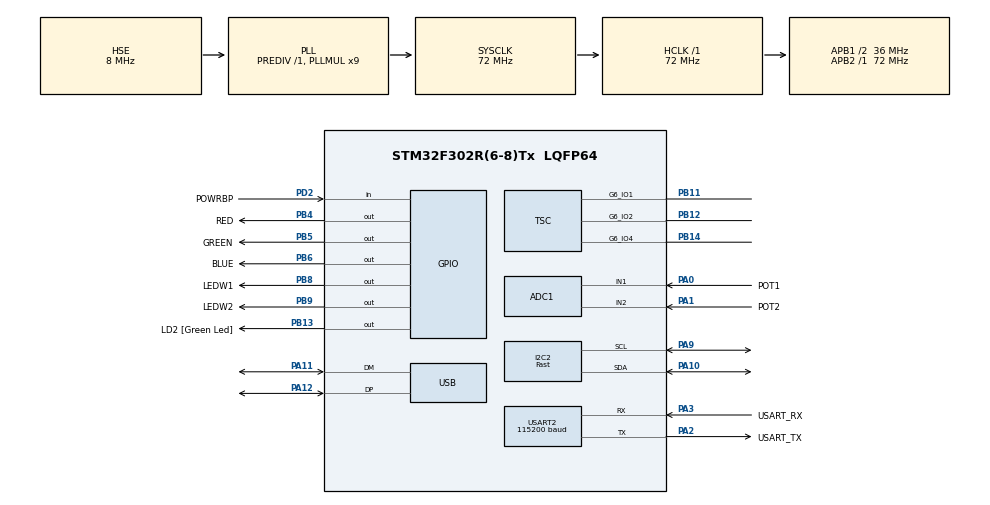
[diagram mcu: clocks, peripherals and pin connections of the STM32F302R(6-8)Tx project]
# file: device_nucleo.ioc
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ADC1.Channel-0\#ChannelRegularConversion=ADC_CHANNEL_1
ADC1.NbrOfConversionFlag=1
ADC1.Offset-0\#ChannelRegularConversion=0
ADC1.OffsetNumber-0\#ChannelRegularConversion=ADC_OFFSET_NONE
ADC1.Rank-0\#ChannelRegularConversion=1
ADC1.SamplingTime-0\#ChannelRegularConversion=ADC_SAMPLETIME_1CYCLE_5
ADC1.SubFamily=STM32F302x8
ADC1.master=1
Dma.ADC1.4.Direction=DMA_PERIPH_TO_MEMORY
Dma.ADC1.4.Instance=DMA1_Channel1
Dma.ADC1.4.MemDataAlignment=DMA_MDATAALIGN_HALFWORD
Dma.ADC1.4.MemInc=DMA_MINC_ENABLE
Dma.ADC1.4.Mode=DMA_NORMAL
Dma.ADC1.4.PeriphDataAlignment=DMA_PDATAALIGN_HALFWORD
Dma.ADC1.4.PeriphInc=DMA_PINC_DISABLE
Dma.ADC1.4.Priority=DMA_PRIORITY_LOW
Dma.I2C2_RX.2.Direction=DMA_PERIPH_TO_MEMORY
Dma.I2C2_RX.2.Instance=DMA1_Channel5
Dma.I2C2_RX.2.MemDataAlignment=DMA_MDATAALIGN_BYTE
Dma.I2C2_RX.2.MemInc=DMA_MINC_ENABLE
Dma.I2C2_RX.2.Mode=DMA_NORMAL
Dma.I2C2_RX.2.PeriphDataAlignment=DMA_PDATAALIGN_BYTE
Dma.I2C2_RX.2.PeriphInc=DMA_PINC_DISABLE
Dma.I2C2_RX.2.Priority=DMA_PRIORITY_LOW
Dma.I2C2_TX.3.Direction=DMA_MEMORY_TO_PERIPH
Dma.I2C2_TX.3.Instance=DMA1_Channel4
Dma.I2C2_TX.3.MemDataAlignment=DMA_MDATAALIGN_BYTE
Dma.I2C2_TX.3.MemInc=DMA_MINC_ENABLE
Dma.I2C2_TX.3.Mode=DMA_NORMAL
Dma.I2C2_TX.3.PeriphDataAlignment=DMA_PDATAALIGN_BYTE
Dma.I2C2_TX.3.PeriphInc=DMA_PINC_DISABLE
Dma.I2C2_TX.3.Priority=DMA_PRIORITY_LOW
Dma.Request0=USART2_RX
Dma.Request1=USART2_TX
Dma.Request2=I2C2_RX
Dma.Request3=I2C2_TX
Dma.Request4=ADC1
Dma.USART2_RX.0.Direction=DMA_PERIPH_TO_MEMORY
Dma.USART2_RX.0.Instance=DMA1_Channel6
Dma.USART2_RX.0.MemDataAlignment=DMA_MDATAALIGN_BYTE
Dma.USART2_RX.0.MemInc=DMA_MINC_ENABLE
Dma.USART2_RX.0.Mode=DMA_NORMAL
Dma.USART2_RX.0.PeriphDataAlignment=DMA_PDATAALIGN_BYTE
Dma.USART2_RX.0.PeriphInc=DMA_PINC_DISABLE
Dma.USART2_RX.0.Priority=DMA_PRIORITY_LOW
Dma.USART2_TX.1.Direction=DMA_MEMORY_TO_PERIPH
Dma.USART2_TX.1.Instance=DMA1_Channel7
Dma.USART2_TX.1.MemDataAlignment=DMA_MDATAALIGN_BYTE
Dma.USART2_TX.1.MemInc=DMA_MINC_ENABLE
Dma.USART2_TX.1.Mode=DMA_NORMAL
Dma.USART2_TX.1.PeriphDataAlignment=DMA_PDATAALIGN_BYTE
Dma.USART2_TX.1.PeriphInc=DMA_PINC_DISABLE
Dma.USART2_TX.1.Priority=DMA_PRIORITY_LOW
I2C2.I2C_Speed_Mode=I2C_Fast
I2C2.Timing=0x0010020A
Mcu.Family=STM32F3
Mcu.Name=STM32F302R(6-8)Tx
Mcu.Package=LQFP64
NVIC.DMA1_Channel1_IRQn=true\:0\:0\:false\:false\:true\:false\:true\:true
NVIC.DMA1_Channel4_IRQn=true\:0\:0\:false\:false\:true\:false\:true\:true
NVIC.DMA1_Channel5_IRQn=true\:0\:0\:false\:false\:true\:false\:true\:true
NVIC.DMA1_Channel6_IRQn=true\:0\:0\:false\:false\:true\:false\:true\:true
NVIC.DMA1_Channel7_IRQn=true\:0\:0\:false\:false\:true\:false\:true\:true
NVIC.PriorityGroup=NVIC_PRIORITYGROUP_0
NVIC.TIM2_IRQn=true\:0\:0\:false\:false\:true\:true\:true\:true
NVIC.USART2_IRQn=true\:0\:0\:false\:false\:true\:true\:true\:true
NVIC.USB_LP_CAN_RX0_IRQn=true\:0\:0\:false\:false\:true\:false\:true\:true
PA0.GPIO_Label=POT1
PA0.Signal=SharedAnalog_PA0
PA1.GPIO_Label=POT2
PA1.Signal=SharedAnalog_PA1
PA10.Mode=I2C
PA10.Signal=I2C2_SDA
PA11.Mode=Device
PA11.Signal=USB_DM
PA12.Mode=Device
PA12.Signal=USB_DP
PA13.GPIO_Label=TMS
PA13.Mode=Serial_Wire
PA13.Signal=SYS_JTMS-SWDIO
PA14.GPIO_Label=TCK
PA14.Mode=Serial_Wire
PA14.Signal=SYS_JTCK-SWCLK
PA2.GPIO_Label=USART_TX
PA2.GPIO_Mode=GPIO_MODE_AF_PP
PA2.GPIO_PuPd=GPIO_NOPULL
PA2.GPIO_Speed=GPIO_SPEED_FREQ_LOW
PA2.Mode=Asynchronous
PA2.Signal=USART2_TX
PA3.GPIO_Label=USART_RX
PA3.GPIO_Mode=GPIO_MODE_AF_PP
PA3.GPIO_PuPd=GPIO_NOPULL
PA3.GPIO_Speed=GPIO_SPEED_FREQ_LOW
PA3.Mode=Asynchronous
PA3.Signal=USART2_RX
PA9.Mode=I2C
PA9.Signal=I2C2_SCL
PB11.Mode=G6_IO1-Channel
PB11.Signal=TSC_G6_IO1
PB12.Mode=G6_IO2-Channel
PB12.Signal=TSC_G6_IO2
PB13.GPIO_Label=LD2 [Green Led]
PB13.Signal=GPIO_Output
PB14.Mode=G6_IO4-Sampling
PB14.Signal=TSC_G6_IO4
PB3.GPIO_Label=SWO
PB3.Mode=Trace_Asynchronous_SW
PB3.Signal=SYS_JTDO-TRACESWO
PB4.GPIO_Label=RED
PB4.Signal=GPIO_Output
PB5.GPIO_Label=GREEN
PB5.Signal=GPIO_Output
PB6.GPIO_Label=BLUE
PB6.Signal=GPIO_Output
PB8.GPIO_Label=LEDW1
PB8.Signal=GPIO_Output
PB9.GPIO_Label=LEDW2
PB9.Signal=GPIO_Output
PC14\ -\ OSC32_IN.Mode=LSE-External-Oscillator
PC14\ -\ OSC32_IN.Signal=RCC_OSC32_IN
PC15\ -\ OSC32_OUT.Mode=LSE-External-Oscillator
PC15\ -\ OSC32_OUT.Signal=RCC_OSC32_OUT
PD2.GPIO_Label=POWRBP
PD2.Signal=GPIO_Input
PF0-OSC_IN.Mode=HSE-External-Oscillator
PF0-OSC_IN.Signal=RCC_OSC_IN
PF1-OSC_OUT.Mode=HSE-External-Oscillator
PF1-OSC_OUT.Signal=RCC_OSC_OUT
ProjectManager.HeapSize=0x200
ProjectManager.StackSize=0x400
ProjectManager.TargetToolchain=STM32CubeIDE
RCC.AHBFreq_Value=72000000
RCC.APB1CLKDivider=RCC_HCLK_DIV2
RCC.APB1Freq_Value=36000000
RCC.APB1TimFreq_Value=72000000
RCC.APB2Freq_Value=72000000
RCC.APB2TimFreq_Value=72000000
RCC.CortexFreq_Value=72000000
RCC.HCLKFreq_Value=72000000
RCC.HSE_VALUE=8000000
RCC.HSI_VALUE=8000000
RCC.PLLM=8
RCC.PLLMUL=RCC_PLL_MUL9
RCC.PLLN=336
RCC.PLLP=RCC_PLLP_DIV4
RCC.PLLQ=7
RCC.PRESCALERUSB=RCC_USBCLKSOURCE_PLL_DIV1_5
RCC.SYSCLKFreq_VALUE=72000000
RCC.SYSCLKSourceVirtual=RCC_SYSCLKSOURCE_PLLCLK
RCC.USBFreq_Value=48000000
SH.SharedAnalog_PA0.0=GPIO_Analog
SH.SharedAnalog_PA0.1=ADC1_IN1,IN1-Single-Ended
SH.SharedAnalog_PA1.0=GPIO_Analog
SH.SharedAnalog_PA1.1=ADC1_IN2,IN2-Single-Ended
TIM2.CounterMode=TIM_COUNTERMODE_UP
TIM2.Period=35999
TIM2.Prescaler=1
TSC.CTPulseHighLength=TSC_CTPH_1CYCLE
TSC.CTPulseLowLength=TSC_CTPL_1CYCLE
TSC.ChannelIOs-G6_IO1=TSC_GROUP6_IO1
TSC.ChannelIOs-G6_IO2=TSC_GROUP6_IO2
TSC.MaxCountValue=TSC_MCV_16383
TSC.PulseGeneratorPrescaler=TSC_PG_PRESC_DIV64
TSC.SamplingIOs-G6_IO4=TSC_GROUP6_IO4
TSC.SpreadSpectrum=DISABLE
TSC.SpreadSpectrumDeviation=127
TSC.SpreadSpectrumPrescaler=TSC_SS_PRESC_DIV2
USART2.BaudRate=115200
USART2.VirtualMode-Asynchronous=VM_ASYNC
USB_DEVICE.APP_RX_DATA_SIZE=512
USB_DEVICE.APP_TX_DATA_SIZE=512
USB_DEVICE.CLASS_NAME_FS=CDC
USB_DEVICE.USBD_MAX_STR_DESC_SIZ=64
USB_DEVICE.VirtualMode=Cdc
USB_DEVICE.VirtualModeFS=Cdc_FS
VP_CRC_VS_CRC.Mode=CRC_Activate
VP_TIM2_VS_ClockSourceINT.Mode=Internal
VP_USB_DEVICE_VS_USB_DEVICE_CDC_FS.Mode=CDC_FS
board=NUCLEO-F302R8

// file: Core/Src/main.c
/* USER CODE BEGIN Header */
/**
 ******************************************************************************
 * @file           : main.c
 * @brief          : Main program body
 ******************************************************************************
 * @attention
 *
 * Copyright (c) 2025 STMicroelectronics.
 * All rights reserved.
 *
 * This software is licensed under terms that can be found in the LICENSE file
 * in the root directory of this software component.
 * If no LICENSE file comes with this software, it is provided AS-IS.
 *
 ******************************************************************************
 */
/* USER CODE END Header */
#include "main.h"
#include "usb_device.h"

/* USER CODE BEGIN Includes */
#include <stdio.h>
#include <string.h>
#include "external_drivers/ssd1306.h"
#include "fsm/fsm.h"
/* USER CODE END Includes */

ADC_HandleTypeDef hadc1;
DMA_HandleTypeDef hdma_adc1;

CRC_HandleTypeDef hcrc;

I2C_HandleTypeDef hi2c2;
DMA_HandleTypeDef hdma_i2c2_rx;
DMA_HandleTypeDef hdma_i2c2_tx;

TIM_HandleTypeDef htim2;

TSC_HandleTypeDef htsc;

UART_HandleTypeDef huart2;
DMA_HandleTypeDef hdma_usart2_rx;
DMA_HandleTypeDef hdma_usart2_tx;

void SystemClock_Config(void);
static void MX_GPIO_Init(void);
static void MX_DMA_Init(void);
static void MX_USART2_UART_Init(void);
static void MX_ADC1_Init(void);
static void MX_TSC_Init(void);
static void MX_CRC_Init(void);
static void MX_I2C2_Init(void);
static void MX_TIM2_Init(void);

int main(void)
{

  /* MCU Configuration--------------------------------------------------------*/

  /* Reset of all peripherals, Initializes the Flash interface and the Systick. */
  HAL_Init();

  /* Configure the system clock */
  SystemClock_Config();

  /* Initialize all configured peripherals */
  MX_GPIO_Init();
  MX_DMA_Init();
  MX_USART2_UART_Init();
  MX_ADC1_Init();
  MX_TSC_Init();
  MX_CRC_Init();
  MX_USB_DEVICE_Init();
  MX_I2C2_Init();
  MX_TIM2_Init();
  /* USER CODE BEGIN 2 */
  SSD1306_Init(&hi2c2);
  fsm_init();

  /* USER CODE END 2 */

  /* Infinite loop */
  while (1)
  {
	  fsm_update();

  }
}

void SystemClock_Config(void)
{
  RCC_OscInitTypeDef RCC_OscInitStruct = {0};
  RCC_ClkInitTypeDef RCC_ClkInitStruct = {0};
  RCC_PeriphCLKInitTypeDef PeriphClkInit = {0};

  /** Initializes the RCC Oscillators according to the specified parameters
  * in the RCC_OscInitTypeDef structure.
  */
  RCC_OscInitStruct.OscillatorType = RCC_OSCILLATORTYPE_HSI|RCC_OSCILLATORTYPE_HSE;
  RCC_OscInitStruct.HSEState = RCC_HSE_ON;
  RCC_OscInitStruct.HSEPredivValue = RCC_HSE_PREDIV_DIV1;
  RCC_OscInitStruct.HSIState = RCC_HSI_ON;
  RCC_OscInitStruct.HSICalibrationValue = RCC_HSICALIBRATION_DEFAULT;
  RCC_OscInitStruct.PLL.PLLState = RCC_PLL_ON;
  RCC_OscInitStruct.PLL.PLLSource = RCC_PLLSOURCE_HSE;
  RCC_OscInitStruct.PLL.PLLMUL = RCC_PLL_MUL9;
  if (HAL_RCC_OscConfig(&RCC_OscInitStruct) != HAL_OK)
  {
    Error_Handler();
  }

  /** Initializes the CPU, AHB and APB buses clocks
  */
  RCC_ClkInitStruct.ClockType = RCC_CLOCKTYPE_HCLK|RCC_CLOCKTYPE_SYSCLK
                              |RCC_CLOCKTYPE_PCLK1|RCC_CLOCKTYPE_PCLK2;
  RCC_ClkInitStruct.SYSCLKSource = RCC_SYSCLKSOURCE_PLLCLK;
  RCC_ClkInitStruct.AHBCLKDivider = RCC_SYSCLK_DIV1;
  RCC_ClkInitStruct.APB1CLKDivider = RCC_HCLK_DIV2;
  RCC_ClkInitStruct.APB2CLKDivider = RCC_HCLK_DIV1;

  if (HAL_RCC_ClockConfig(&RCC_ClkInitStruct, FLASH_LATENCY_2) != HAL_OK)
  {
    Error_Handler();
  }
  PeriphClkInit.PeriphClockSelection = RCC_PERIPHCLK_USB|RCC_PERIPHCLK_I2C2
                              |RCC_PERIPHCLK_ADC1;
  PeriphClkInit.I2c2ClockSelection = RCC_I2C2CLKSOURCE_HSI;
  PeriphClkInit.USBClockSelection = RCC_USBCLKSOURCE_PLL_DIV1_5;
  PeriphClkInit.Adc1ClockSelection = RCC_ADC1PLLCLK_DIV1;

  if (HAL_RCCEx_PeriphCLKConfig(&PeriphClkInit) != HAL_OK)
  {
    Error_Handler();
  }
}

static void MX_ADC1_Init(void)
{

  ADC_ChannelConfTypeDef sConfig = {0};

  /** Common config
  */
  hadc1.Instance = ADC1;
  hadc1.Init.ClockPrescaler = ADC_CLOCK_ASYNC_DIV1;
  hadc1.Init.Resolution = ADC_RESOLUTION_12B;
  hadc1.Init.ScanConvMode = ADC_SCAN_DISABLE;
  hadc1.Init.ContinuousConvMode = DISABLE;
  hadc1.Init.DiscontinuousConvMode = DISABLE;
  hadc1.Init.ExternalTrigConvEdge = ADC_EXTERNALTRIGCONVEDGE_NONE;
  hadc1.Init.ExternalTrigConv = ADC_SOFTWARE_START;
  hadc1.Init.DataAlign = ADC_DATAALIGN_RIGHT;
  hadc1.Init.NbrOfConversion = 1;
  hadc1.Init.DMAContinuousRequests = DISABLE;
  hadc1.Init.EOCSelection = ADC_EOC_SINGLE_CONV;
  hadc1.Init.LowPowerAutoWait = DISABLE;
  hadc1.Init.Overrun = ADC_OVR_DATA_OVERWRITTEN;
  if (HAL_ADC_Init(&hadc1) != HAL_OK)
  {
    Error_Handler();
  }

  /** Configure Regular Channel
  */
  sConfig.Channel = ADC_CHANNEL_1;
  sConfig.Rank = ADC_REGULAR_RANK_1;
  sConfig.SingleDiff = ADC_SINGLE_ENDED;
  sConfig.SamplingTime = ADC_SAMPLETIME_1CYCLE_5;
  sConfig.OffsetNumber = ADC_OFFSET_NONE;
  sConfig.Offset = 0;
  if (HAL_ADC_ConfigChannel(&hadc1, &sConfig) != HAL_OK)
  {
    Error_Handler();
  }

}

static void MX_CRC_Init(void)
{

  hcrc.Instance = CRC;
  hcrc.Init.DefaultPolynomialUse = DEFAULT_POLYNOMIAL_ENABLE;
  hcrc.Init.DefaultInitValueUse = DEFAULT_INIT_VALUE_ENABLE;
  hcrc.Init.InputDataInversionMode = CRC_INPUTDATA_INVERSION_NONE;
  hcrc.Init.OutputDataInversionMode = CRC_OUTPUTDATA_INVERSION_DISABLE;
  hcrc.InputDataFormat = CRC_INPUTDATA_FORMAT_BYTES;
  if (HAL_CRC_Init(&hcrc) != HAL_OK)
  {
    Error_Handler();
  }

}

static void MX_I2C2_Init(void)
{

  hi2c2.Instance = I2C2;
  hi2c2.Init.Timing = 0x0010020A;
  hi2c2.Init.OwnAddress1 = 0;
  hi2c2.Init.AddressingMode = I2C_ADDRESSINGMODE_7BIT;
  hi2c2.Init.DualAddressMode = I2C_DUALADDRESS_DISABLE;
  hi2c2.Init.OwnAddress2 = 0;
  hi2c2.Init.OwnAddress2Masks = I2C_OA2_NOMASK;
  hi2c2.Init.GeneralCallMode = I2C_GENERALCALL_DISABLE;
  hi2c2.Init.NoStretchMode = I2C_NOSTRETCH_DISABLE;
  if (HAL_I2C_Init(&hi2c2) != HAL_OK)
  {
    Error_Handler();
  }

  /** Configure Analogue filter
  */
  if (HAL_I2CEx_ConfigAnalogFilter(&hi2c2, I2C_ANALOGFILTER_ENABLE) != HAL_OK)
  {
    Error_Handler();
  }

  /** Configure Digital filter
  */
  if (HAL_I2CEx_ConfigDigitalFilter(&hi2c2, 0) != HAL_OK)
  {
    Error_Handler();
  }

}

static void MX_TIM2_Init(void)
{

  TIM_ClockConfigTypeDef sClockSourceConfig = {0};
  TIM_MasterConfigTypeDef sMasterConfig = {0};

  htim2.Instance = TIM2;
  htim2.Init.Prescaler = 1;
  htim2.Init.CounterMode = TIM_COUNTERMODE_UP;
  htim2.Init.Period = 35999;
  htim2.Init.ClockDivision = TIM_CLOCKDIVISION_DIV1;
  htim2.Init.AutoReloadPreload = TIM_AUTORELOAD_PRELOAD_DISABLE;
  if (HAL_TIM_Base_Init(&htim2) != HAL_OK)
  {
    Error_Handler();
  }
  sClockSourceConfig.ClockSource = TIM_CLOCKSOURCE_INTERNAL;
  if (HAL_TIM_ConfigClockSource(&htim2, &sClockSourceConfig) != HAL_OK)
  {
    Error_Handler();
  }
  sMasterConfig.MasterOutputTrigger = TIM_TRGO_RESET;
  sMasterConfig.MasterSlaveMode = TIM_MASTERSLAVEMODE_DISABLE;
  if (HAL_TIMEx_MasterConfigSynchronization(&htim2, &sMasterConfig) != HAL_OK)
  {
    Error_Handler();
  }

}

static void MX_TSC_Init(void)
{

  /** Configure the TSC peripheral
  */
  htsc.Instance = TSC;
  htsc.Init.CTPulseHighLength = TSC_CTPH_1CYCLE;
  htsc.Init.CTPulseLowLength = TSC_CTPL_1CYCLE;
  htsc.Init.SpreadSpectrum = DISABLE;
  htsc.Init.SpreadSpectrumDeviation = 127;
  htsc.Init.SpreadSpectrumPrescaler = TSC_SS_PRESC_DIV2;
  htsc.Init.PulseGeneratorPrescaler = TSC_PG_PRESC_DIV64;
  htsc.Init.MaxCountValue = TSC_MCV_16383;
  htsc.Init.IODefaultMode = TSC_IODEF_OUT_PP_LOW;
  htsc.Init.SynchroPinPolarity = TSC_SYNC_POLARITY_FALLING;
  htsc.Init.AcquisitionMode = TSC_ACQ_MODE_NORMAL;
  htsc.Init.MaxCountInterrupt = DISABLE;
  htsc.Init.ChannelIOs = TSC_GROUP6_IO1|TSC_GROUP6_IO2;
  htsc.Init.ShieldIOs = 0;
  htsc.Init.SamplingIOs = TSC_GROUP6_IO4;
  if (HAL_TSC_Init(&htsc) != HAL_OK)
  {
    Error_Handler();
  }

}

static void MX_USART2_UART_Init(void)
{

  huart2.Instance = USART2;
  huart2.Init.BaudRate = 115200;
  huart2.Init.WordLength = UART_WORDLENGTH_8B;
  huart2.Init.StopBits = UART_STOPBITS_1;
  huart2.Init.Parity = UART_PARITY_NONE;
  huart2.Init.Mode = UART_MODE_TX_RX;
  huart2.Init.HwFlowCtl = UART_HWCONTROL_NONE;
  huart2.Init.OverSampling = UART_OVERSAMPLING_16;
  huart2.Init.OneBitSampling = UART_ONE_BIT_SAMPLE_DISABLE;
  huart2.AdvancedInit.AdvFeatureInit = UART_ADVFEATURE_NO_INIT;
  if (HAL_UART_Init(&huart2) != HAL_OK)
  {
    Error_Handler();
  }

}

static void MX_DMA_Init(void)
{

  /* DMA controller clock enable */
  __HAL_RCC_DMA1_CLK_ENABLE();

  /* DMA interrupt init */
  /* DMA1_Channel1_IRQn interrupt configuration */
  HAL_NVIC_SetPriority(DMA1_Channel1_IRQn, 0, 0);
  HAL_NVIC_EnableIRQ(DMA1_Channel1_IRQn);
  /* DMA1_Channel4_IRQn interrupt configuration */
  HAL_NVIC_SetPriority(DMA1_Channel4_IRQn, 0, 0);
  HAL_NVIC_EnableIRQ(DMA1_Channel4_IRQn);
  /* DMA1_Channel5_IRQn interrupt configuration */
  HAL_NVIC_SetPriority(DMA1_Channel5_IRQn, 0, 0);
  HAL_NVIC_EnableIRQ(DMA1_Channel5_IRQn);
  /* DMA1_Channel6_IRQn interrupt configuration */
  HAL_NVIC_SetPriority(DMA1_Channel6_IRQn, 0, 0);
  HAL_NVIC_EnableIRQ(DMA1_Channel6_IRQn);
  /* DMA1_Channel7_IRQn interrupt configuration */
  HAL_NVIC_SetPriority(DMA1_Channel7_IRQn, 0, 0);
  HAL_NVIC_EnableIRQ(DMA1_Channel7_IRQn);

}

static void MX_GPIO_Init(void)
{
  GPIO_InitTypeDef GPIO_InitStruct = {0};

  /* GPIO Ports Clock Enable */
  __HAL_RCC_GPIOC_CLK_ENABLE();
  __HAL_RCC_GPIOF_CLK_ENABLE();
  __HAL_RCC_GPIOA_CLK_ENABLE();
  __HAL_RCC_GPIOB_CLK_ENABLE();
  __HAL_RCC_GPIOD_CLK_ENABLE();

  /*Configure GPIO pin Output Level */
  HAL_GPIO_WritePin(GPIOB, LD2_Pin|RED_Pin|GREEN_Pin|BLUE_Pin
                          |LEDW1_Pin|LEDW2_Pin, GPIO_PIN_RESET);

  /*Configure GPIO pins : LD2_Pin RED_Pin GREEN_Pin BLUE_Pin
                           LEDW1_Pin LEDW2_Pin */
  GPIO_InitStruct.Pin = LD2_Pin|RED_Pin|GREEN_Pin|BLUE_Pin
                          |LEDW1_Pin|LEDW2_Pin;
  GPIO_InitStruct.Mode = GPIO_MODE_OUTPUT_PP;
  GPIO_InitStruct.Pull = GPIO_NOPULL;
  GPIO_InitStruct.Speed = GPIO_SPEED_FREQ_LOW;
  HAL_GPIO_Init(GPIOB, &GPIO_InitStruct);

  /*Configure GPIO pin : POWRBP_Pin */
  GPIO_InitStruct.Pin = POWRBP_Pin;
  GPIO_InitStruct.Mode = GPIO_MODE_INPUT;
  GPIO_InitStruct.Pull = GPIO_NOPULL;
  HAL_GPIO_Init(POWRBP_GPIO_Port, &GPIO_InitStruct);

}

void Error_Handler(void)
{
  __disable_irq();
  while (1)
  {
  }
}
